# NAVSS0_CPTS_0_CPTS register map
Vendor: Texas Instruments
Peripheral module from a debugger description file (folder J7_AHP).
Registers are 32-bit, read-write, reset 0x0 unless marked. A register's access mark holds for its fields unless they carry their own. Offsets are as the file gives them; lines under a group give offsets from that group; [hi:lo] are bit positions; {n}, {i} and the like mark numbered series; 'fields as' and 'values as' point back to an identical list; <NAME> marks a mode.

## NAVSS0_CPTS_0_CPTS
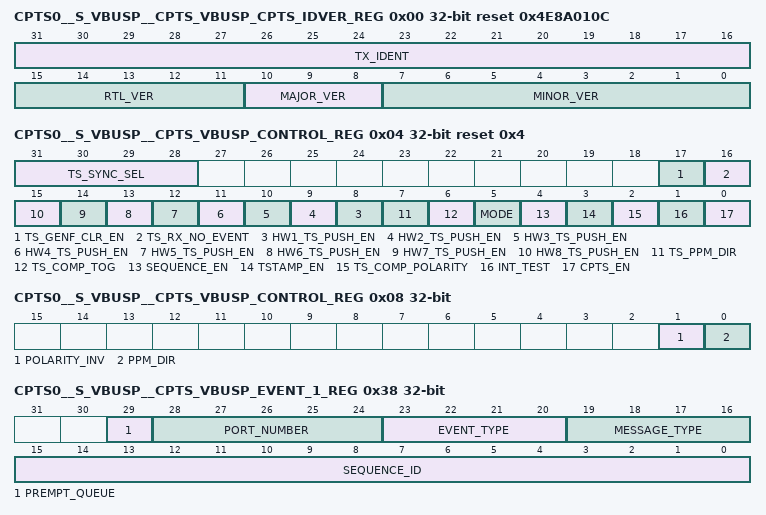
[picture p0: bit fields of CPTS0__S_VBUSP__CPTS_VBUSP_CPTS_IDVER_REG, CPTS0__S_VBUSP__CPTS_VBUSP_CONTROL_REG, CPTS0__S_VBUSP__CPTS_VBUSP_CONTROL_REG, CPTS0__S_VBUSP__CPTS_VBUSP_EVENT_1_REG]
0x00 CPTS0__S_VBUSP__CPTS_VBUSP_CPTS_IDVER_REG ro reset 0x4E8A010C
  [31:16] TX_IDENT — Identification value
  [15:11] RTL_VER — RTL version value
  [10:8] MAJOR_VER — Major version value
  [7:0] MINOR_VER — Minor version value
0x00 CPTS0__S_VBUSP__CPTS_VBUSP_COMP_LOW_REG
  [31:0] COMP_LOW — Time Stamp Generate Function Comparison Low Value
0x00 CPTS0__S_VBUSP__CPTS_VBUSP_COMP_LOW_REG
  [31:0] COMP_LOW — Time Stamp ESTF Generate Function Comparison Low Value
0x04 CPTS0__S_VBUSP__CPTS_VBUSP_CONTROL_REG reset 0x4
  [31:28] TS_SYNC_SEL — TS_SYNC output timestamp counter bit select
  [17] TS_GENF_CLR_EN — Enable for GENF clear when length is zero
  [16] TS_RX_NO_EVENT — Receive Produces no Events
  [n+7] HW{n}_TS_PUSH_EN (n=1..8) — Hardware push {n} enable
  [7] TS_PPM_DIR — Timestamp PPM Direction
  [6] TS_COMP_TOG — Timestamp Compare Toggle mode: 0=TS_COMP is in non-toggle mode, 1=TS_COMP is in toggle mode
  [5] MODE — Timestamp mode
  [4] SEQUENCE_EN — Sequence Enable
  [3] TSTAMP_EN — Host Receive Timestamp Enable
  [2] TS_COMP_POLARITY
  [1] INT_TEST — Interrupt test
  [0] CPTS_EN — Time sync enable
0x04 CPTS0__S_VBUSP__CPTS_VBUSP_COMP_HIGH_REG
  [31:0] COMP_HIGH — Time Stamp Generate Function Comparison High Value
0x04 CPTS0__S_VBUSP__CPTS_VBUSP_COMP_HIGH_REG
  [31:0] COMP_HIGH — Time Stamp ESTF Generate Function Comparison High Value
0x08 CPTS0__S_VBUSP__CPTS_VBUSP_RFTCLK_SEL_REG
  [4:0] RFTCLK_SEL — Reference clock select
0x08 CPTS0__S_VBUSP__CPTS_VBUSP_CONTROL_REG
  [1] POLARITY_INV — Time Stamp Generate Function Polarity Invert
  [0] PPM_DIR — Time Stamp Generate Function PPM Direction
0x08 CPTS0__S_VBUSP__CPTS_VBUSP_CONTROL_REG
  [1] POLARITY_INV — Time Stamp ESTF Generate Function Polarity Invert
  [0] PPM_DIR — Time Stamp ESTF Generate Function PPM Direction
0x0C CPTS0__S_VBUSP__CPTS_VBUSP_TS_PUSH_REG wo
  [0] TS_PUSH — Time stamp event push
0x0C CPTS0__S_VBUSP__CPTS_VBUSP_LENGTH_REG
  [31:0] LENGTH — Time Stamp Generate Function Length Value
0x0C CPTS0__S_VBUSP__CPTS_VBUSP_LENGTH_REG
  [31:0] LENGTH — Time Stamp ESTF Generate Function Length Value
0x10 CPTS0__S_VBUSP__CPTS_VBUSP_TS_LOAD_LOW_VAL_REG
  [31:0] TS_LOAD_VAL — Time stamp load low value
0x10 CPTS0__S_VBUSP__CPTS_VBUSP_PPM_LOW_REG
  [31:0] PPM_LOW — Time Stamp Generate Function PPM Low Value
0x10 CPTS0__S_VBUSP__CPTS_VBUSP_PPM_LOW_REG
  [31:0] PPM_LOW — Time Stamp ESTF Generate Function PPM Low Value
0x14 CPTS0__S_VBUSP__CPTS_VBUSP_TS_LOAD_EN_REG wo
  [0] TS_LOAD_EN — Time stamp load enable
0x14 CPTS0__S_VBUSP__CPTS_VBUSP_PPM_HIGH_REG
  [9:0] PPM_HIGH — Time Stamp Generate Function PPM High Value
0x14 CPTS0__S_VBUSP__CPTS_VBUSP_PPM_HIGH_REG
  [9:0] PPM_HIGH — Time Stamp ESTF Generate Function PPM High Value
0x18 CPTS0__S_VBUSP__CPTS_VBUSP_TS_COMP_LOW_VAL_REG
  [31:0] TS_COMP_VAL — Time stamp comparison low value
0x18 CPTS0__S_VBUSP__CPTS_VBUSP_NUDGE_REG
  [7:0] NUDGE — Time Stamp Generate Function Nudge Value
0x18 CPTS0__S_VBUSP__CPTS_VBUSP_NUDGE_REG
  [7:0] NUDGE — Time Stamp ESTF Generate Function Nudge Value
0x1C CPTS0__S_VBUSP__CPTS_VBUSP_TS_COMP_LEN_REG
  [31:0] TS_COMP_LENGTH — Time stamp comparison length
0x20 CPTS0__S_VBUSP__CPTS_VBUSP_INTSTAT_RAW_REG
  [0] TS_PEND_RAW — TS_PEND_RAW int read (before enable)
0x24 CPTS0__S_VBUSP__CPTS_VBUSP_INTSTAT_MASKED_REG ro
  [0] TS_PEND — TS_PEND masked interrupt read (after enable)
0x28 CPTS0__S_VBUSP__CPTS_VBUSP_INT_ENABLE_REG
  [0] TS_PEND_EN — TS_PEND masked interrupt enable
0x2C CPTS0__S_VBUSP__CPTS_VBUSP_TS_COMP_NUDGE_REG
  [7:0] NUDGE — This 2s complement number is added to the ts_comp_length value to increase or decrease the TS_COMP length by the nudge amount
0x30 CPTS0__S_VBUSP__CPTS_VBUSP_EVENT_POP_REG wo
  [0] EVENT_POP
0x34 CPTS0__S_VBUSP__CPTS_VBUSP_EVENT_0_REG ro
  [31:0] TIME_STAMP
0x38 CPTS0__S_VBUSP__CPTS_VBUSP_EVENT_1_REG ro
  [29] PREMPT_QUEUE, [28:24] PORT_NUMBER, [23:20] EVENT_TYPE, [19:16] MESSAGE_TYPE, [15:0] SEQUENCE_ID
0x3C CPTS0__S_VBUSP__CPTS_VBUSP_EVENT_2_REG ro
  [7:0] DOMAIN
0x40 CPTS0__S_VBUSP__CPTS_VBUSP_EVENT_3_REG ro
  [31:0] TIME_STAMP
0x44 CPTS0__S_VBUSP__CPTS_VBUSP_TS_LOAD_HIGH_VAL_REG
  [31:0] TS_LOAD_VAL — Time stamp load high value
0x48 CPTS0__S_VBUSP__CPTS_VBUSP_TS_COMP_HIGH_VAL_REG
  [31:0] TS_COMP_HIGH_VAL — Time stamp comparison high value
0x4C CPTS0__S_VBUSP__CPTS_VBUSP_TS_ADD_VAL_REG
  [2:0] ADD_VAL — Add Value
0x50 CPTS0__S_VBUSP__CPTS_VBUSP_TS_PPM_LOW_VAL_REG
  [31:0] TS_PPM_LOW_VAL — Time stamp PPM Low value
0x54 CPTS0__S_VBUSP__CPTS_VBUSP_TS_PPM_HIGH_VAL_REG
  [9:0] TS_PPM_HIGH_VAL — Time stamp PPM High value
0x58 CPTS0__S_VBUSP__CPTS_VBUSP_TS_NUDGE_VAL_REG
  [7:0] TS_NUDGE_VAL — Time stamp Nudge value
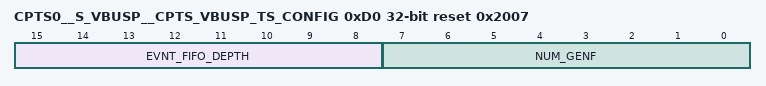
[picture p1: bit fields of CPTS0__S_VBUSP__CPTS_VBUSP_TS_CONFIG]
0xD0 CPTS0__S_VBUSP__CPTS_VBUSP_TS_CONFIG ro reset 0x2007
  [15:8] EVNT_FIFO_DEPTH — The Event FIFO Depth
  [7:0] NUM_GENF — The number of CPTS GENF outputs
